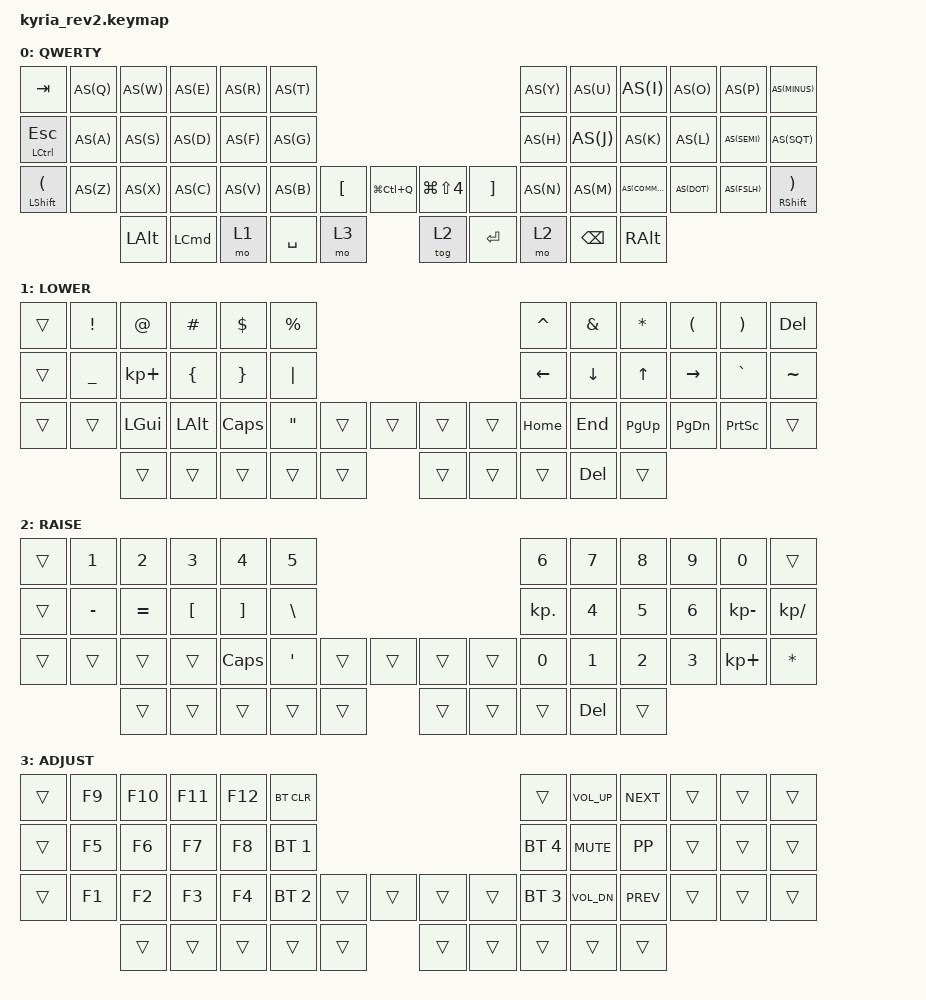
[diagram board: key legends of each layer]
/*
 * Copyright (c) 2020 The ZMK Contributors
 *
 * SPDX-License-Identifier: MIT
 */

#include <behaviors.dtsi>
#include <dt-bindings/zmk/keys.h>
#include <dt-bindings/zmk/bt.h>

#define QWERTY 0
#define LOWER 1
#define RAISE 2
#define ADJUST 3

#define AS(keycode) &as LS(keycode) keycode

#define CTR_ESC &mt LCTRL ESC
#define L_SHFT_PAR &mt LSHFT LPAR
#define R_SHFT_PAR &mt RSHFT RPAR
#define LCK_SCN &kp LG(LC(Q))
#define SCSHT &kp LG(LS(N4))

&mt {
	tapping_term_ms = <150>;
};

/ {
	behaviors {
		as: auto_shift {
			compatible = "zmk,behavior-hold-tap";
			label = "AUTO_SHIFT";
			#binding-cells = <2>;
			tapping_term_ms = <175>;
			quick_tap_ms = <0>;
			flavor = "tap-preferred";
			bindings = <&kp>, <&kp>;
		};
	};

	keymap {
		compatible = "zmk,keymap";

		default_layer {
			label = "QWERTY";
/*
 * ,-------------------------------------------.                              ,-------------------------------------------.
 * |  Tab   |   Q  |   W  |   E  |   R  |   T  |                              |   Y  |   U  |   I  |   O  |   P  |   -    |
 * |--------+------+------+------+------+------|                              |------+------+------+------+------+--------|
 * |Ctrl/Esc|   A  |   S  |   D  |   F  |   G  |                              |   H  |   J  |   K  |   L  | ;  : |  '  "  |
 * |--------+------+------+------+------+------+-------------.  ,-------------+------+------+------+------+------+--------|
 * | (LShft |   Z  |   X  |   C  |   V  |   B  | [ {  |LCKSRN|  |SCSHT |  ] } |   N  |   M  | ,  < | . >  | /  ? | RShft) |
 * `----------------------+------+------+------+------+------|  |------+------+------+------+------+----------------------'
 *                        | LALT | LGUI | Lower| Space|Adjust|  |Numpad| Enter| Raise| Bskp |  PP  |
 *                        `----------------------------------'  `----------------------------------'
 */
			bindings = <
	&kp TAB    AS(Q) AS(W) AS(E) AS(R) AS(T)                                                AS(Y) AS(U)    AS(I)     AS(O)   AS(P)    AS(MINUS)
	CTR_ESC    AS(A) AS(S) AS(D) AS(F) AS(G)                                                AS(H) AS(J)    AS(K)     AS(L)   AS(SEMI) AS(SQT)
	L_SHFT_PAR AS(Z) AS(X) AS(C) AS(V) AS(B) &kp LBKT  LCK_SCN      SCSHT    &kp RBKT       AS(N) AS(M)    AS(COMMA) AS(DOT) AS(FSLH) R_SHFT_PAR
	                 &kp LALT &kp LCMD &mo 1 &kp SPACE &mo 3        &tog 2   &kp RET        &mo 2 &kp BSPC &kp RALT
			>;
		};

		lower_layer {
			label = "LOWER";
/*
 * Lower Layer: symbols, navigation
 *
 * ,-------------------------------------------.                              ,-------------------------------------------.
 * |        |  !   |   @  |   #  |  $   |  %   |                              |  ^   |  &   |   *  |  (   |  )   | Delete |
 * |--------+------+------+------+------+------|                              |------+------+------+------+------+--------|
 * |        |  _   |  +   |  {   |  }   |  |   |                              |  ←   |  ↓   |   ↑  |   →  |  `   |   ~    |
 * |--------+------+------+------+------+------+-------------.  ,-------------+------+------+------+------+------+--------|
 * |        | ESC  |      |      | CAPS |   "  |      |      |  | SCSHT|      | HOME | PGDWN| PGUP |  END |      |        |
 * `----------------------+------+------+------+------+------|  |------+------+------+------+------+----------------------'
 *                        |      |      |      |      |      |  |      |      |      |  DEL |      |
 *                        `----------------------------------'  `----------------------------------'
 */
			bindings = <
	&trans &kp EXCL  &kp AT      &kp HASH &kp DLLR &kp PRCNT                              &kp CARET &kp AMPS &kp ASTRK &kp LPAR  &kp RPAR  &kp DEL
	&trans &kp UNDER &kp KP_PLUS &kp LBRC &kp RBRC &kp PIPE                               &kp LEFT  &kp DOWN &kp UP    &kp RIGHT &kp GRAVE &kp TILDE
	&trans &trans    &kp LGUI    &kp LALT &kp CLCK &kp DQT &trans &trans    &trans &trans &kp HOME  &kp END  &kp PG_UP &kp PG_DN &kp PSCRN &trans
			                     &trans   &trans   &trans  &trans &trans    &trans &trans &trans    &kp DEL  &trans
			>;
		};

		raise_layer {
			label = "RAISE";
/*
 * Raise Layer: Numbers and symbols
 *
 * ,-------------------------------------------.                              ,-------------------------------------------.
 * |        |  1   |  2   |  3   |  4   |  5   |                              |   6  |  7   |  8   |  9   |  0   |   =    |
 * |--------+------+------+------+------+------|                              |------+------+------+------+------+--------|
 * |        |  -   |  =   |  [   |  ]   |  \   |                              |   .  |  4   |  5   |  6   |  -   |   /    |
 * |--------+------+------+------+------+------+-------------.  ,-------------+------+------+------+------+------+--------|
 * |        |      |      |      | CAPS |  '   |  {   |      |  |      |   }  |   0  |  1   |  2   |  3   |  +   |   *    |
 * `----------------------+------+------+------+------+------|  |------+------+------+------+------+----------------------'
 *                        |      |      |      |      |      |  |      |      | Enter|      |      |
 *                        `----------------------------------'  `----------------------------------'
 */
			bindings = <
	&trans &kp N1    &kp N2    &kp N3    &kp N4    &kp N5                                  &kp N6     &kp N7    &kp N8    &kp N9    &kp N0       &trans
	&trans &kp MINUS &kp EQUAL &kp LBKT  &kp RBKT  &kp BSLH                                &kp KP_DOT &kp N4    &kp N5    &kp N6    &kp KP_MINUS &kp KP_SLASH
	&trans &trans    &trans    &trans    &kp CLCK  &kp SQT  &trans &trans    &trans &trans &kp N0     &kp N1    &kp N2    &kp N3    &kp KP_PLUS  &kp ASTRK
	                           &trans    &trans    &trans   &trans &trans    &trans &trans &trans    &kp DEL  &trans
			>;
		};

		adjust_layer {
			label = "ADJUST";
/*
 * Function Layer: Function, media
 *
 * ,---------------------------------------------.                              ,-------------------------------------------.
 * |        |  F9  | F10  | F11  | F12  | BT_CLR |                              |      | VLUP | Next |      |      |        |
 * |--------+------+------+------+------+--------|                              |------+------+------+------+------+--------|
 * |        |  F5  |  F6  |  F7  |  F8  |  BT_1  |                              | BT_4 | MUTE | Play |      |      |        |
 * |--------+------+------+------+------+------+---------------.  ,-------------+------+------+------+------+------+--------|
 * |        |  F1  |  F2  |  F3  |  F4  |  BT_2  |      |      |  |      |      | BT_3 | VLDN | Prev |      |      |        |
 * `----------------------+------+------+------+------+--------|  |------+------+------+------+------+----------------------'
 *                        |      |      |        |      |      |  |      |      |      |      |      |
 *                        |      |      |        |      |      |  |      |      |      |      |      |
 *                        `----------------------------------'  `----------------------------------'
 */
			bindings = <
	&trans &kp F9 &kp F10 &kp F11 &kp F12 &bt BT_CLR                                   &trans        &kp K_VOL_UP  &kp K_NEXT  &trans  &trans  &trans
	&trans &kp F5 &kp F6  &kp F7  &kp F8  &bt BT_SEL 1                                 &bt BT_SEL 4  &kp K_MUTE    &kp K_PP    &trans  &trans  &trans
	&trans &kp F1 &kp F2  &kp F3  &kp F4  &bt BT_SEL 2  &trans &trans    &trans &trans &bt BT_SEL 3  &kp K_VOL_DN  &kp K_PREV  &trans  &trans  &trans
	                      &trans  &trans  &trans        &trans &trans    &trans &trans &trans        &trans        &trans
			>;
		};
	};
};
